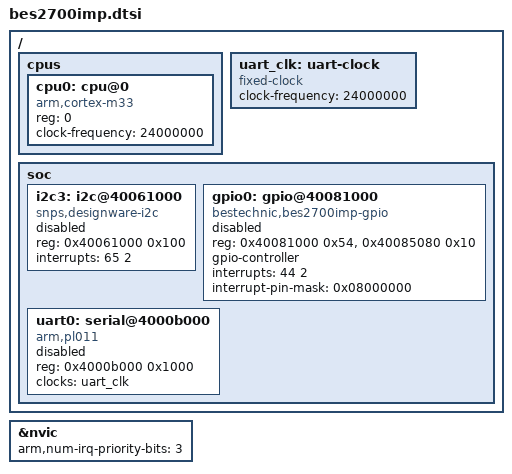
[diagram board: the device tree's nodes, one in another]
/*
 * SPDX-FileCopyrightText: Copyright The Zephyr Project Contributors
 * SPDX-License-Identifier: Apache-2.0
 */

#include <arm/armv8-m.dtsi>
#include <mem.h>

/ {
	cpus {
		#address-cells = <1>;
		#size-cells = <0>;

		cpu0: cpu@0 {
			device_type = "cpu";
			compatible = "arm,cortex-m33";
			reg = <0>;
			clock-frequency = <24000000>;
		};
	};

	uart_clk: uart-clock {
		compatible = "fixed-clock";
		#clock-cells = <0>;
		clock-frequency = <24000000>;
	};
	soc {
		i2c3: i2c@40061000 {
			compatible = "snps,designware-i2c";
			reg = <0x40061000 0x100>;
			interrupts = <65 2>;
			#address-cells = <1>;
			#size-cells = <0>;
			status = "disabled";
		};

		gpio0: gpio@40081000 {
			compatible = "bestechnic,bes2700imp-gpio";
			reg = <0x40081000 0x54>, <0x40085080 0x10>;
			reg-names = "gpio", "psc";
			gpio-controller;
			#gpio-cells = <2>;
			interrupts = <44 2>;
			interrupt-pin-mask = <0x08000000>;
			status = "disabled";
		};

		uart0: serial@4000b000 {
			compatible = "arm,pl011";
			reg = <0x4000b000 0x1000>;
			clocks = <&uart_clk>;
			status = "disabled";
		};
	};
};

&nvic {
	arm,num-irq-priority-bits = <3>;
};
